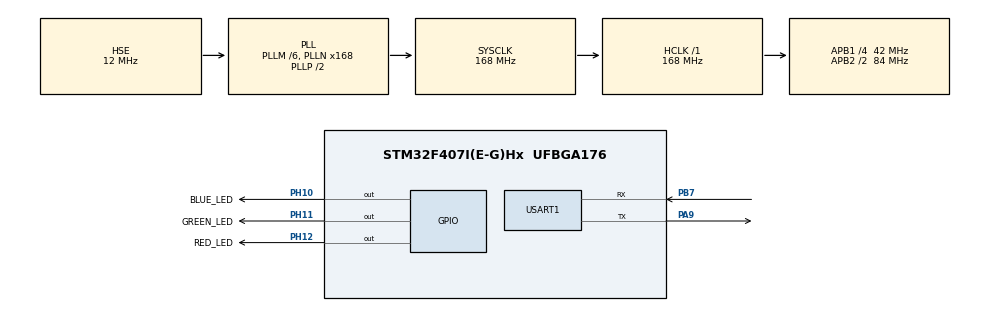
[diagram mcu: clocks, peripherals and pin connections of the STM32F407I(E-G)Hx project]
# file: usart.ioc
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Mcu.Family=STM32F4
Mcu.Name=STM32F407I(E-G)Hx
Mcu.Package=UFBGA176
NVIC.PriorityGroup=NVIC_PRIORITYGROUP_4
NVIC.USART1_IRQn=true\:0\:0\:false\:false\:true\:true\:true\:true
PA13.Mode=Serial_Wire
PA13.Signal=SYS_JTMS-SWDIO
PA14.Mode=Serial_Wire
PA14.Signal=SYS_JTCK-SWCLK
PA9.Mode=Asynchronous
PA9.Signal=USART1_TX
PB7.Mode=Asynchronous
PB7.Signal=USART1_RX
PH0-OSC_IN.Mode=HSE-External-Oscillator
PH0-OSC_IN.Signal=RCC_OSC_IN
PH1-OSC_OUT.Mode=HSE-External-Oscillator
PH1-OSC_OUT.Signal=RCC_OSC_OUT
PH10.GPIO_Label=BLUE_LED
PH10.Signal=GPIO_Output
PH11.GPIO_Label=GREEN_LED
PH11.Signal=GPIO_Output
PH12.GPIO_Label=RED_LED
PH12.Signal=GPIO_Output
ProjectManager.HeapSize=0x200
ProjectManager.StackSize=0x400
ProjectManager.TargetToolchain=CMake
RCC.48MHZClocksFreq_Value=84000000
RCC.AHBFreq_Value=168000000
RCC.APB1CLKDivider=RCC_HCLK_DIV4
RCC.APB1Freq_Value=42000000
RCC.APB1TimFreq_Value=84000000
RCC.APB2CLKDivider=RCC_HCLK_DIV2
RCC.APB2Freq_Value=84000000
RCC.APB2TimFreq_Value=168000000
RCC.CortexFreq_Value=168000000
RCC.HCLKFreq_Value=168000000
RCC.HSE_VALUE=12000000
RCC.HSI_VALUE=16000000
RCC.LSE_VALUE=32768
RCC.PLLM=6
RCC.PLLN=168
RCC.PLLSourceVirtual=RCC_PLLSOURCE_HSE
RCC.SYSCLKFreq_VALUE=168000000
RCC.SYSCLKSource=RCC_SYSCLKSOURCE_PLLCLK
RCC.VCOOutputFreq_Value=336000000
USART1.VirtualMode=VM_ASYNC
board=custom

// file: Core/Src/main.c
/* USER CODE BEGIN Header */
/**
  ******************************************************************************
  * @file           : main.c
  * @brief          : Main program body
  ******************************************************************************
  * @attention
  *
  * Copyright (c) 2026 STMicroelectronics.
  * All rights reserved.
  *
  * This software is licensed under terms that can be found in the LICENSE file
  * in the root directory of this software component.
  * If no LICENSE file comes with this software, it is provided AS-IS.
  *
  ******************************************************************************
  */
/* USER CODE END Header */
#include "main.h"
#include "usart.h"
#include "gpio.h"

/* USER CODE BEGIN PV */
uint8_t str[] = "Hello, UART IT Mode!\r\n";
/* USER CODE END PV */

void SystemClock_Config(void);

int main(void)
{

    /* MCU Configuration--------------------------------------------------------*/

    /* Reset of all peripherals, Initializes the Flash interface and the Systick. */
    HAL_Init();

    /* Configure the system clock */
    SystemClock_Config();

    /* Initialize all configured peripherals */
    MX_GPIO_Init();
    MX_USART1_UART_Init();
    /* USER CODE BEGIN 2 */
    HAL_GPIO_WritePin(GPIOH, GREEN_LED_Pin, RESET); // 初始化绿灯灭
    /* USER CODE END 2 */

    /* Infinite loop */
    /* USER CODE BEGIN WHILE */
    while (1)
    {
        /*  sizeof算的是内存大小 编译期就确定了 包含\0
            strlen运行时计算不包含\0
            char str1[] = "hello";
            char *str2 = "hello";
            sizeof(str1) = 6字节
            sizeof(str2) = 4字节
            总结:
            定长字符串用sizeof(str1) - 1
            不定长字符串用strlen(str1)
            指针类型的字符串 只能用strlen(str1)
          */
        HAL_GPIO_WritePin(GPIOH, GREEN_LED_Pin, SET);  // 绿灯亮
        // 启动中断发送 注意：这里只是启动，立刻就会往下执行，不会阻塞
        if (HAL_UART_Transmit_IT(&huart1, str, sizeof(str) - 1) != HAL_OK)
        {
            // 如果启动失败（比如上一次还没发完），强制切回空闲状态
            HAL_GPIO_WritePin(GPIOH, GREEN_LED_Pin, RESET);
        }
        HAL_Delay(1000);
        /* USER CODE END WHILE */

    }
}

void SystemClock_Config(void)
{
    RCC_OscInitTypeDef RCC_OscInitStruct = {0};
    RCC_ClkInitTypeDef RCC_ClkInitStruct = {0};

    /** Configure the main internal regulator output voltage
    */
    __HAL_RCC_PWR_CLK_ENABLE();
    __HAL_PWR_VOLTAGESCALING_CONFIG(PWR_REGULATOR_VOLTAGE_SCALE1);

    /** Initializes the RCC Oscillators according to the specified parameters
    * in the RCC_OscInitTypeDef structure.
    */
    RCC_OscInitStruct.OscillatorType = RCC_OSCILLATORTYPE_HSE;
    RCC_OscInitStruct.HSEState = RCC_HSE_ON;
    RCC_OscInitStruct.PLL.PLLState = RCC_PLL_ON;
    RCC_OscInitStruct.PLL.PLLSource = RCC_PLLSOURCE_HSE;
    RCC_OscInitStruct.PLL.PLLM = 6;
    RCC_OscInitStruct.PLL.PLLN = 168;
    RCC_OscInitStruct.PLL.PLLP = RCC_PLLP_DIV2;
    RCC_OscInitStruct.PLL.PLLQ = 4;
    if (HAL_RCC_OscConfig(&RCC_OscInitStruct) != HAL_OK)
    {
        Error_Handler();
    }

    /** Initializes the CPU, AHB and APB buses clocks
    */
    RCC_ClkInitStruct.ClockType = RCC_CLOCKTYPE_HCLK | RCC_CLOCKTYPE_SYSCLK
                                  | RCC_CLOCKTYPE_PCLK1 | RCC_CLOCKTYPE_PCLK2;
    RCC_ClkInitStruct.SYSCLKSource = RCC_SYSCLKSOURCE_PLLCLK;
    RCC_ClkInitStruct.AHBCLKDivider = RCC_SYSCLK_DIV1;
    RCC_ClkInitStruct.APB1CLKDivider = RCC_HCLK_DIV4;
    RCC_ClkInitStruct.APB2CLKDivider = RCC_HCLK_DIV2;

    if (HAL_RCC_ClockConfig(&RCC_ClkInitStruct, FLASH_LATENCY_5) != HAL_OK)
    {
        Error_Handler();
    }
}

/* USER CODE BEGIN 4 */
// 发送完成回调函数
// 当 UART 硬件把最后一个字节发完后，HAL 库会自动调用这个函数
void HAL_UART_TxCpltCallback(UART_HandleTypeDef *huart)
{
    // 判断是不是我们要的 USART1
    if (huart->Instance == USART1)
    {
        HAL_GPIO_WritePin(GPIOH, GREEN_LED_Pin, RESET); // 绿灯灭
    }
}
/* USER CODE END 4 */

void Error_Handler(void)
{
    __disable_irq();
    while (1)
    {
    }
}
